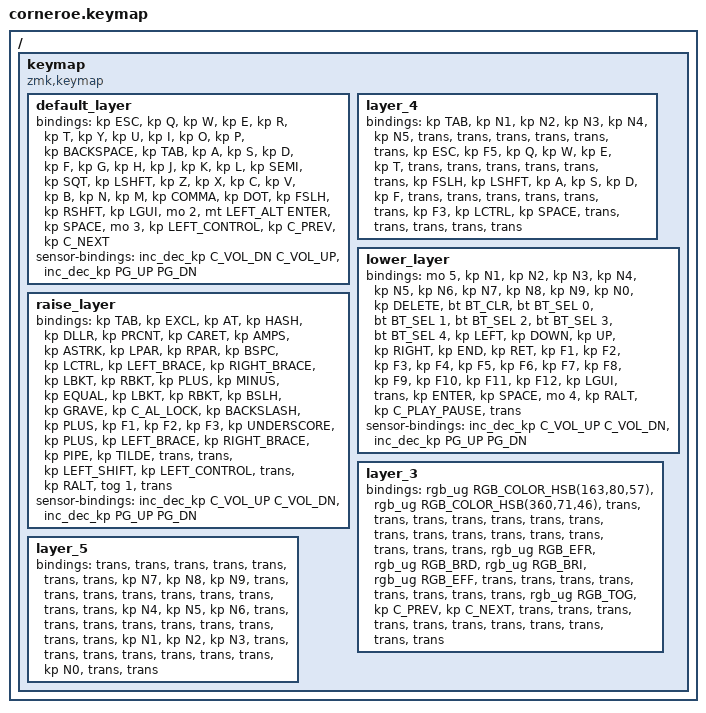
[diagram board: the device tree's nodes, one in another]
/*
 * Copyright (c) 2020 The ZMK Contributors
 *
 * SPDX-License-Identifier: MIT
 */

#include <dt-bindings/zmk/mouse.h>
#include <behaviors.dtsi>
#include <dt-bindings/zmk/bt.h>
#include <dt-bindings/zmk/keys.h>
#include <dt-bindings/zmk/rgb.h>

/ {
    keymap {
        compatible = "zmk,keymap";

        default_layer {
            // -----------------------------------------------------------------------------------------
            // |  TAB |  Q  |  W  |  E  |  R  |  T  |   |  Y  |  U   |  I  |  O  |  P  | BSPC |
            // | CTRL |  A  |  S  |  D  |  F  |  G  |   |  H  |  J   |  K  |  L  |  ;  |  '   |
            // | SHFT |  Z  |  X  |  C  |  V  |  B  |   |  N  |  M   |  ,  |  .  |  /  | ESC  |
            //                    | GUI | LWR | SPC |   | ENT | RSE  | ALT |

            bindings = <
&kp ESC  &kp Q  &kp W  &kp E  &kp R  &kp T  &kp Y  &kp U  &kp I  &kp O  &kp P  &kp BACKSPACE  &kp TAB  &kp A  &kp S  &kp D  &kp F  &kp G  &kp H  &kp J  &kp K  &kp L  &kp SEMI  &kp SQT  &kp LSHFT  &kp Z  &kp X  &kp C  &kp V  &kp B  &kp N  &kp M  &kp COMMA  &kp DOT  &kp FSLH  &kp RSHFT  &kp LGUI  &mo 2  &mt LEFT_ALT ENTER  &kp SPACE  &mo 3  &kp LEFT_CONTROL  &kp C_PREV  &kp C_NEXT
            >;

            sensor-bindings = <&inc_dec_kp C_VOL_DN C_VOL_UP &inc_dec_kp PG_UP PG_DN>;
        };

        layer_4 {
            bindings = <
&kp TAB  &kp N1  &kp N2  &kp N3  &kp N4  &kp N5  &trans  &trans  &trans  &trans  &trans  &trans  &kp ESC  &kp F5  &kp Q  &kp W  &kp E  &kp T  &trans  &trans  &trans  &trans  &trans  &trans  &kp FSLH  &kp LSHFT  &kp A  &kp S  &kp D  &kp F  &trans  &trans  &trans  &trans  &trans  &trans  &kp F3  &kp LCTRL  &kp SPACE  &trans  &trans  &trans  &trans  &trans
            >;
        };

        lower_layer {
            // -----------------------------------------------------------------------------------------
            // |  TAB |  1  |  2  |  3  |  4  |  5  |   |  6  |  7  |  8  |  9  |  0  | BSPC |
            // | BTCLR| BT1 | BT2 | BT3 | BT4 | BT5 |   | LFT | DWN |  UP | RGT |     |      |
            // | SHFT |     |     |     |     |     |   |     |     |     |     |     |      |
            //                    | GUI |     | SPC |   | ENT |     | ALT |

            bindings = <
&mo 5  &kp N1  &kp N2  &kp N3  &kp N4  &kp N5  &kp N6  &kp N7  &kp N8  &kp N9  &kp N0  &kp DELETE  &bt BT_CLR  &bt BT_SEL 0  &bt BT_SEL 1  &bt BT_SEL 2  &bt BT_SEL 3  &bt BT_SEL 4  &kp LEFT  &kp DOWN  &kp UP  &kp RIGHT  &kp END  &kp RET  &kp F1  &kp F2  &kp F3  &kp F4  &kp F5  &kp F6  &kp F7  &kp F8  &kp F9  &kp F10  &kp F11  &kp F12  &kp LGUI  &trans  &kp ENTER  &kp SPACE  &mo 4  &kp RALT  &kp C_PLAY_PAUSE  &trans
            >;

            sensor-bindings = <&inc_dec_kp C_VOL_UP C_VOL_DN &inc_dec_kp PG_UP PG_DN>;
        };

        raise_layer {
            // -----------------------------------------------------------------------------------------
            // |  TAB |  !  |  @  |  #  |  $  |  %  |   |  ^  |  &  |  *  |  (  |  )  | BSPC |
            // | CTRL |     |     |     |     |     |   |  -  |  =  |  [  |  ]  |  \  |  `   |
            // | SHFT |     |     |     |     |     |   |  _  |  +  |  {  |  }  | "|" |  ~   |
            //                    | GUI |     | SPC |   | ENT |     | ALT |

            bindings = <
&kp TAB  &kp EXCL  &kp AT  &kp HASH  &kp DLLR  &kp PRCNT  &kp CARET  &kp AMPS  &kp ASTRK  &kp LPAR  &kp RPAR  &kp BSPC  &kp LCTRL  &kp LEFT_BRACE  &kp RIGHT_BRACE  &kp LBKT  &kp RBKT  &kp PLUS  &kp MINUS  &kp EQUAL  &kp LBKT  &kp RBKT  &kp BSLH  &kp GRAVE  &kp C_AL_LOCK  &kp BACKSLASH  &kp PLUS  &kp F1  &kp F2  &kp F3  &kp UNDERSCORE  &kp PLUS  &kp LEFT_BRACE  &kp RIGHT_BRACE  &kp PIPE  &kp TILDE  &trans  &trans  &kp LEFT_SHIFT  &kp LEFT_CONTROL  &trans  &kp RALT  &tog 1  &trans
            >;

            sensor-bindings = <&inc_dec_kp C_VOL_UP C_VOL_DN &inc_dec_kp PG_UP PG_DN>;
        };

        layer_3 {
            bindings = <
&rgb_ug RGB_COLOR_HSB(163,80,57)  &rgb_ug RGB_COLOR_HSB(360,71,46)  &trans  &trans  &trans  &trans  &trans  &trans  &trans  &trans  &trans  &trans  &trans  &trans  &trans  &trans  &trans  &trans  &rgb_ug RGB_EFR  &rgb_ug RGB_BRD  &rgb_ug RGB_BRI  &rgb_ug RGB_EFF  &trans  &trans  &trans  &trans  &trans  &trans  &trans  &trans  &rgb_ug RGB_TOG  &kp C_PREV  &kp C_NEXT  &trans  &trans  &trans  &trans  &trans  &trans  &trans  &trans  &trans  &trans  &trans
            >;
        };

        layer_5 {
            bindings = <
&trans  &trans  &trans  &trans  &trans  &trans  &trans  &kp N7  &kp N8  &kp N9  &trans  &trans  &trans  &trans  &trans  &trans  &trans  &trans  &trans  &kp N4  &kp N5  &kp N6  &trans  &trans  &trans  &trans  &trans  &trans  &trans  &trans  &trans  &kp N1  &kp N2  &kp N3  &trans  &trans  &trans  &trans  &trans  &trans  &trans  &kp N0  &trans  &trans
            >;
        };
    };
};
